# Cortex_M7 register map
Vendor: Arm Ltd.; Series: ARMv7E-M; File version: 1.0.0
CPU: CM7 r0p0, little endian, MPU, FPU, double-precision FPU, DSP, 8 interrupt priority bits
Registers are 32-bit, read-write, reset 0x0 unless marked. A register's access mark holds for its fields unless they carry their own. Offsets are from the block's base; [hi:lo] are bit positions.

## SCnSCB — System control registers not in the SCB: the interrupt controller type and the implementation-defined Auxiliary Control Register.
Base 0xE000E000
0x04 ICTR ro — Interrupt Controller Type Register: how many interrupt lines the NVIC supports, in groups of 32. Read-only.
  [3:0] INTLINESNUM — Number of interrupt lines in groups of 32: the NVIC supports up to 32 x (INTLINESNUM+1) interrupts (0 = 1-32, 1 = 33-64, ...).
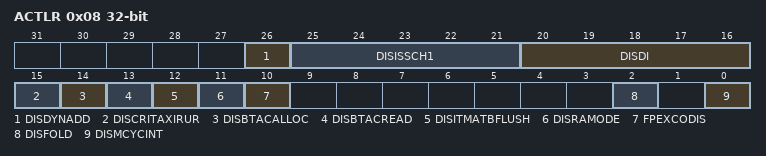
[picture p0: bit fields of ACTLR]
0x08 ACTLR — Auxiliary Control Register: implementation-defined controls that disable individual performance features (write buffering, instruction folding, interruptible multi-cycle instructions, FPU behaviours). Usually left at reset; DISDEFWBUF is useful to make imprecise BusFaults precise while debugging.
  [26] DISDYNADD — 1 = disable dynamic allocation of ADD/SUB instructions to the two issue channels (Cortex-M7 r1).
  [25:21] DISISSCH1 — Disable issue channel 1 per instruction class (Cortex-M7): forces those instructions onto channel 0.
  [20:16] DISDI — Disable dual issue: one bit per instruction class (Cortex-M7 TRM table) - set to force single issue of that class.
  [15] DISCRITAXIRUR — 1 = disable critical-word-first AXI read-under-read.
  [14] DISBTACALLOC — 1 = disable allocation into the Branch Target Address Cache.
  [13] DISBTACREAD — 1 = disable reading the Branch Target Address Cache (static prediction only).
  [12] DISITMATBFLUSH — 1 = disable the ITM and DWT ATB flush handshake.
  [11] DISRAMODE — 1 = disable the dynamic read-allocate mode of the data cache (Cortex-M7 switches to write-allocate-only for streaming writes when set).
  [10] FPEXCODIS — 1 = disable the FPU exception outputs (FPIXC, FPUFC, FPOFC, FPDZC, FPIDC, FPIOC); the cumulative FPSCR flags still update.
  [2] DISFOLD — 1 = disable IT-block folding (Cortex-M3/M4) / instruction folding (Cortex-M7).
  [0] DISMCYCINT — 1 = multi-cycle instructions (LDM, STM, 64-bit loads/stores, MVE) are not interruptible - worst-case interrupt latency rises but becomes deterministic.

## SysTick — 24-bit system timer that counts down from LOAD to 0 on the processor or reference clock and can raise the SysTick exception; the usual RTOS tick source. Banked per security state on ARMv8-M with the Security Extension.
Base 0xE000E010
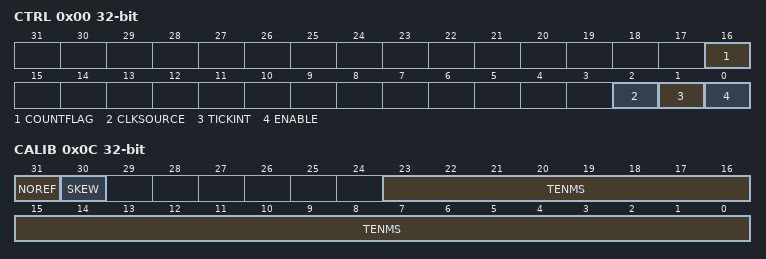
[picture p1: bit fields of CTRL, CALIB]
0x00 CTRL — SysTick Control and Status Register: enable, interrupt enable, clock source and the sticky count-to-zero flag.
  [16] COUNTFLAG ro — Reads 1 if the counter reached 0 since the last read of this register. Cleared by reading CTRL or writing VAL.
  [2] CLKSOURCE — Clock source: 0 = external reference clock (implementation defined, e.g. HCLK/8), 1 = processor clock.
    0=External reference clock (implementation defined); 1=Processor clock
  [1] TICKINT — 1 = counting down to 0 sets the SysTick exception pending; 0 = poll COUNTFLAG instead.
  [0] ENABLE — Counter enable: 1 = SysTick counts down from LOAD to 0 and reloads.
0x04 LOAD — SysTick Reload Value Register: value loaded into VAL when the counter reaches 0. A period of N clocks needs RELOAD = N-1.
  [23:0] RELOAD — Value loaded into VAL when the counter reaches 0. A period of N clocks needs RELOAD = N-1; 0 is legal but the counter then never fires.
0x08 VAL — SysTick Current Value Register: the current count. Any write clears it to 0 and clears CTRL.COUNTFLAG; the next reload comes from LOAD.
  [23:0] CURRENT — Current counter value. Any write clears the field to 0 and clears CTRL.COUNTFLAG.
0x0C CALIB ro — SysTick Calibration Register: implementation-defined reload value for a 10 ms tick and whether a reference clock exists.
  [31] NOREF — 1 = no separate reference clock: CLKSOURCE reads 1 and cannot be cleared.
  [30] SKEW — 1 = TENMS is not exact (a 10 ms tick cannot be produced exactly).
  [23:0] TENMS — Reload value for a 10 ms period with the reference clock, or 0 if unknown. Implementation defined.
